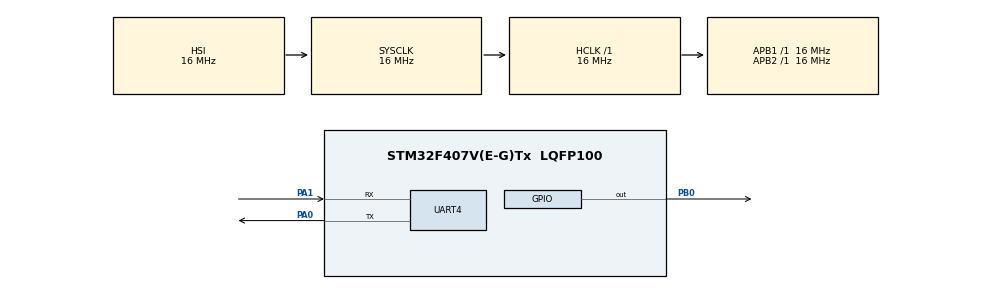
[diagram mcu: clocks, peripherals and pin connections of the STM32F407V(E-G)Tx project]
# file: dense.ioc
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Mcu.Family=STM32F4
Mcu.Name=STM32F407V(E-G)Tx
Mcu.Package=LQFP100
NVIC.PriorityGroup=NVIC_PRIORITYGROUP_4
PA0-WKUP.Mode=Asynchronous
PA0-WKUP.Signal=UART4_TX
PA1.Mode=Asynchronous
PA1.Signal=UART4_RX
PB0.Signal=GPIO_Output
ProjectManager.HeapSize=0x800
ProjectManager.StackSize=0x800
ProjectManager.TargetToolchain=Makefile
RCC.AHBFreq_Value=16000000
RCC.APB1Freq_Value=16000000
RCC.APB2Freq_Value=16000000
RCC.CortexFreq_Value=16000000
RCC.HSE_VALUE=25000000
RCC.HSI_VALUE=16000000
RCC.LSE_VALUE=32768
RCC.SYSCLKFreq_VALUE=16000000
RCC.VCOOutputFreq_Value=192000000
STMicroelectronics.X-CUBE-AI.4.1.0.ActivationBufferSizeList=40
STMicroelectronics.X-CUBE-AI.4.1.0.ApplicationCcArtificialOoIntelligenceJjApplication=Validation
STMicroelectronics.X-CUBE-AI.4.1.0.ArtificialOoIntelligenceJjApplication.cmp_version0=4.1.0
STMicroelectronics.X-CUBE-AI.4.1.0.ArtificialOoIntelligenceJjApplication.component0=Artificial Intelligence
STMicroelectronics.X-CUBE-AI.4.1.0.ArtificialOoIntelligenceJjApplication.description0=AI Application,Validation on Target
STMicroelectronics.X-CUBE-AI.4.1.0.ArtificialOoIntelligenceJjApplication.diagnostic0=This component should operate correctly.
STMicroelectronics.X-CUBE-AI.4.1.0.ArtificialOoIntelligenceJjApplication.documentation0=Documentation/index.html
STMicroelectronics.X-CUBE-AI.4.1.0.ArtificialOoIntelligenceJjApplication.group0=Application
STMicroelectronics.X-CUBE-AI.4.1.0.ArtificialOoIntelligenceJjApplication.paramName0=ApplicationCcArtificialOoIntelligenceJjApplication
STMicroelectronics.X-CUBE-AI.4.1.0.ArtificialOoIntelligenceJjApplication.sevirity0=none
STMicroelectronics.X-CUBE-AI.4.1.0.ArtificialOoIntelligenceJjApplication.variant0=Validation
STMicroelectronics.X-CUBE-AI.4.1.0.ArtificialOoIntelligenceJjApplication_bundle=Application
STMicroelectronics.X-CUBE-AI.4.1.0.ArtificialOoIntelligenceJjApplication_class=ArtificialOoIntelligence
STMicroelectronics.X-CUBE-AI.4.1.0.ArtificialOoIntelligenceJjApplication_name=X-CUBE-AI
STMicroelectronics.X-CUBE-AI.4.1.0.ArtificialOoIntelligenceJjApplication_size=1
STMicroelectronics.X-CUBE-AI.4.1.0.ArtificialOoIntelligenceJjApplication_vendor=STMicroelectronics
STMicroelectronics.X-CUBE-AI.4.1.0.ArtificialOoIntelligenceJjApplication_version=4.1.0
STMicroelectronics.X-CUBE-AI.4.1.0.ArtificialOoIntelligenceJjXAaCUBEAaAI.cmp_version0=4.1.0
STMicroelectronics.X-CUBE-AI.4.1.0.ArtificialOoIntelligenceJjXAaCUBEAaAI.component0=Artificial Intelligence
STMicroelectronics.X-CUBE-AI.4.1.0.ArtificialOoIntelligenceJjXAaCUBEAaAI.componentDoc0=nofile
STMicroelectronics.X-CUBE-AI.4.1.0.ArtificialOoIntelligenceJjXAaCUBEAaAI.description0=AI Core,Artificial Intelligence for STM32
STMicroelectronics.X-CUBE-AI.4.1.0.ArtificialOoIntelligenceJjXAaCUBEAaAI.diagnostic0=This component should operate correctly.
STMicroelectronics.X-CUBE-AI.4.1.0.ArtificialOoIntelligenceJjXAaCUBEAaAI.documentation0=Documentation/index.html
STMicroelectronics.X-CUBE-AI.4.1.0.ArtificialOoIntelligenceJjXAaCUBEAaAI.group0=Core
STMicroelectronics.X-CUBE-AI.4.1.0.ArtificialOoIntelligenceJjXAaCUBEAaAI.paramName0=XAaCUBEAaAICcArtificialOoIntelligenceJjCore
STMicroelectronics.X-CUBE-AI.4.1.0.ArtificialOoIntelligenceJjXAaCUBEAaAI.sevirity0=none
STMicroelectronics.X-CUBE-AI.4.1.0.ArtificialOoIntelligenceJjXAaCUBEAaAI_bundle=X-CUBE-AI
STMicroelectronics.X-CUBE-AI.4.1.0.ArtificialOoIntelligenceJjXAaCUBEAaAI_class=ArtificialOoIntelligence
STMicroelectronics.X-CUBE-AI.4.1.0.ArtificialOoIntelligenceJjXAaCUBEAaAI_name=X-CUBE-AI
STMicroelectronics.X-CUBE-AI.4.1.0.ArtificialOoIntelligenceJjXAaCUBEAaAI_size=1
STMicroelectronics.X-CUBE-AI.4.1.0.ArtificialOoIntelligenceJjXAaCUBEAaAI_vendor=STMicroelectronics
STMicroelectronics.X-CUBE-AI.4.1.0.ArtificialOoIntelligenceJjXAaCUBEAaAI_version=4.1.0
STMicroelectronics.X-CUBE-AI.4.1.0.HeapSize=0x800
STMicroelectronics.X-CUBE-AI.4.1.0.InternalRamActivationBufferMaxSize=AI_NETWORK_DATA_ACTIVATIONS_SIZE
STMicroelectronics.X-CUBE-AI.4.1.0.LatestDirectoryUsed-478d0beb4ce12c76428d81ba17a9bec7de5affbbac7ac4d617456a0664080c5e=/home/zingg/AIOnMCU/implementation/models
STMicroelectronics.X-CUBE-AI.4.1.0.ModelActualCompression-478d0beb4ce12c76428d81ba17a9bec7de5affbbac7ac4d617456a0664080c5e=0.0
STMicroelectronics.X-CUBE-AI.4.1.0.ModelCompression-478d0beb4ce12c76428d81ba17a9bec7de5affbbac7ac4d617456a0664080c5e=8
STMicroelectronics.X-CUBE-AI.4.1.0.ModelFlashOccupation-478d0beb4ce12c76428d81ba17a9bec7de5affbbac7ac4d617456a0664080c5e=4024
STMicroelectronics.X-CUBE-AI.4.1.0.ModelHashList=478d0beb4ce12c76428d81ba17a9bec7de5affbbac7ac4d617456a0664080c5e
STMicroelectronics.X-CUBE-AI.4.1.0.ModelKind-478d0beb4ce12c76428d81ba17a9bec7de5affbbac7ac4d617456a0664080c5e=KERAS
STMicroelectronics.X-CUBE-AI.4.1.0.ModelMacc-478d0beb4ce12c76428d81ba17a9bec7de5affbbac7ac4d617456a0664080c5e=7990
STMicroelectronics.X-CUBE-AI.4.1.0.ModelName-478d0beb4ce12c76428d81ba17a9bec7de5affbbac7ac4d617456a0664080c5e=network
STMicroelectronics.X-CUBE-AI.4.1.0.ModelNameList=network
STMicroelectronics.X-CUBE-AI.4.1.0.ModelRamOccupation-478d0beb4ce12c76428d81ba17a9bec7de5affbbac7ac4d617456a0664080c5e=40
STMicroelectronics.X-CUBE-AI.4.1.0.ModelStructureFile-478d0beb4ce12c76428d81ba17a9bec7de5affbbac7ac4d617456a0664080c5e=/home/zingg/AIOnMCU/implementation/models/mnist_min.h5
STMicroelectronics.X-CUBE-AI.4.1.0.ModelType-478d0beb4ce12c76428d81ba17a9bec7de5affbbac7ac4d617456a0664080c5e=Saved model
STMicroelectronics.X-CUBE-AI.4.1.0.StackSize=0x800
STMicroelectronics.X-CUBE-AI.4.1.0.WorkingBufferStartAddrList=0xFFFFFFFF
STMicroelectronics.X-CUBE-AI.4.1.0.XAaCUBEAaAICcArtificialOoIntelligenceJjCore=true
STMicroelectronics.X-CUBE-AI.4.1.0_ArtificialOoIntelligenceJjApplication_RteComponent0=\#define AI_VALIDATION
STMicroelectronics.X-CUBE-AI.4.1.0_ArtificialOoIntelligenceJjApplication_RteComponentsize=1
STMicroelectronics.X-CUBE-AI.4.1.0_ArtificialOoIntelligenceJjXAaCUBEAaAI_RteComponentsize=0
STMicroelectronics.X-CUBE-AI.4.1.0_MwName0=X-CUBE-AI
STMicroelectronics.X-CUBE-AI.4.1.0_MwName1=Application
STMicroelectronics.X-CUBE-AI.4.1.0_NumberOfMw=2
STMicroelectronics.X-CUBE-AI.4.1.0_description=Artificial Intelligence
STMicroelectronics.X-CUBE-AI.4.1.0_license=SLA0048.txt
UART4.VirtualMode=Asynchronous
VP_CRC_VS_CRC.Mode=CRC_Activate
VP_STMicroelectronics.X-CUBE-AI_VS_ArtificialOoIntelligenceJjXAaCUBEAaAI_4.1.0.Mode=ArtificialOoIntelligenceJjXAaCUBEAaAI
board=custom

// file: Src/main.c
/* USER CODE BEGIN Header */
/**
  ******************************************************************************
  * @file           : main.c
  * @brief          : Main program body
  ******************************************************************************
  * This notice applies to any and all portions of this file
  * that are not between comment pairs USER CODE BEGIN and
  * USER CODE END. Other portions of this file, whether
  * inserted by the user or by software development tools
  * are owned by their respective copyright owners.
  *
  * Copyright (c) 2019 STMicroelectronics International N.V.
  * All rights reserved.
  *
  * Redistribution and use in source and binary forms, with or without
  * modification, are permitted, provided that the following conditions are met:
  *
  * 1. Redistribution of source code must retain the above copyright notice,
  *    this list of conditions and the following disclaimer.
  * 2. Redistributions in binary form must reproduce the above copyright notice,
  *    this list of conditions and the following disclaimer in the documentation
  *    and/or other materials provided with the distribution.
  * 3. Neither the name of STMicroelectronics nor the names of other
  *    contributors to this software may be used to endorse or promote products
  *    derived from this software without specific written permission.
  * 4. This software, including modifications and/or derivative works of this
  *    software, must execute solely and exclusively on microcontroller or
  *    microprocessor devices manufactured by or for STMicroelectronics.
  * 5. Redistribution and use of this software other than as permitted under
  *    this license is void and will automatically terminate your rights under
  *    this license.
  *
  * THIS SOFTWARE IS PROVIDED BY STMICROELECTRONICS AND CONTRIBUTORS "AS IS"
  * AND ANY EXPRESS, IMPLIED OR STATUTORY WARRANTIES, INCLUDING, BUT NOT
  * LIMITED TO, THE IMPLIED WARRANTIES OF MERCHANTABILITY, FITNESS FOR A
  * PARTICULAR PURPOSE AND NON-INFRINGEMENT OF THIRD PARTY INTELLECTUAL PROPERTY
  * RIGHTS ARE DISCLAIMED TO THE FULLEST EXTENT PERMITTED BY LAW. IN NO EVENT
  * SHALL STMICROELECTRONICS OR CONTRIBUTORS BE LIABLE FOR ANY DIRECT, INDIRECT,
  * INCIDENTAL, SPECIAL, EXEMPLARY, OR CONSEQUENTIAL DAMAGES (INCLUDING, BUT NOT
  * LIMITED TO, PROCUREMENT OF SUBSTITUTE GOODS OR SERVICES; LOSS OF USE, DATA,
  * OR PROFITS; OR BUSINESS INTERRUPTION) HOWEVER CAUSED AND ON ANY THEORY OF
  * LIABILITY, WHETHER IN CONTRACT, STRICT LIABILITY, OR TORT (INCLUDING
  * NEGLIGENCE OR OTHERWISE) ARISING IN ANY WAY OUT OF THE USE OF THIS SOFTWARE,
  * EVEN IF ADVISED OF THE POSSIBILITY OF SUCH DAMAGE.
  *
  ******************************************************************************
  */
/* USER CODE END Header */

#include "main.h"
#include "app_x-cube-ai.h"

/* USER CODE BEGIN PD */
#define IMAGE_SIZE 784 /* MMNIST images have 28*28 pixels */

/* USER CODE END PD */

CRC_HandleTypeDef hcrc;

UART_HandleTypeDef huart4;

void SystemClock_Config(void);
static void MX_GPIO_Init(void);
static void MX_CRC_Init(void);
void MX_UART4_Init(void);

int main(void)
{
  /* USER CODE BEGIN 1 */
  uint8_t pred;
  uint16_t i;
  float mnist[IMAGE_SIZE * 2];
  uint8_t inputPicture[IMAGE_SIZE * 2];
  /* USER CODE END 1 */

  /* MCU Configuration--------------------------------------------------------*/

  /* Reset of all peripherals, Initializes the Flash interface and the Systick. */
  HAL_Init();

  /* Configure the system clock */
  SystemClock_Config();

  /* USER CODE BEGIN SysInit */
  MX_UART4_Init();

  /* USER CODE END SysInit */

  /* Initialize all configured peripherals */
  MX_GPIO_Init();
  MX_CRC_Init();
  MX_X_CUBE_AI_Init();

  /* Infinite loop */
  /* USER CODE BEGIN WHILE */
  while (1)
  {
    /* receive command */
    if (HAL_UART_Receive(&huart4, &pred, 1, 200) != HAL_OK)
      continue;

    switch (pred - 0)
    {
    case 's':
      /* handshake: receive 's' return 'X' */
      pred = 'X' + 0;
      HAL_UART_Transmit(&huart4, &pred, 1, 1000);
      pred = 2;
      HAL_UART_Transmit(&huart4, &pred, 1, 1000);
      break;

    case 'c':
      /* receive a picture from host */
      if (HAL_UART_Receive(&huart4, inputPicture, IMAGE_SIZE, 200) == HAL_OK)
      {

        /* scale into float range [0, 1] */
        for (i = 0; i < IMAGE_SIZE; i++)
          mnist[i] = ((float)inputPicture[i]) / 255.0;

        /* start time measurement */
        HAL_GPIO_WritePin(GPIOB, GPIO_PIN_0, GPIO_PIN_SET);

        /* run neural network to get a prediction of inputPicture */
        pred = MX_X_CUBE_AI_Process(mnist);

        /* stop time measurement */
        HAL_GPIO_WritePin(GPIOB, GPIO_PIN_0, GPIO_PIN_RESET);

        /* return the prediction */
        HAL_UART_Transmit(&huart4, &pred, 1U, 1000);
      }
      break;
    }
  }
  /* USER CODE END WHILE */
}

void SystemClock_Config(void)
{
  RCC_OscInitTypeDef RCC_OscInitStruct = {0};
  RCC_ClkInitTypeDef RCC_ClkInitStruct = {0};

  /** Configure the main internal regulator output voltage
  */
  __HAL_RCC_PWR_CLK_ENABLE();
  __HAL_PWR_VOLTAGESCALING_CONFIG(PWR_REGULATOR_VOLTAGE_SCALE1);
  /** Initializes the CPU, AHB and APB busses clocks
  */
  RCC_OscInitStruct.OscillatorType = RCC_OSCILLATORTYPE_HSI;
  RCC_OscInitStruct.HSIState = RCC_HSI_ON;
  RCC_OscInitStruct.HSICalibrationValue = RCC_HSICALIBRATION_DEFAULT;
  RCC_OscInitStruct.PLL.PLLState = RCC_PLL_NONE;
  if (HAL_RCC_OscConfig(&RCC_OscInitStruct) != HAL_OK)
  {
    Error_Handler();
  }
  /** Initializes the CPU, AHB and APB busses clocks
  */
  RCC_ClkInitStruct.ClockType = RCC_CLOCKTYPE_HCLK | RCC_CLOCKTYPE_SYSCLK | RCC_CLOCKTYPE_PCLK1 | RCC_CLOCKTYPE_PCLK2;
  RCC_ClkInitStruct.SYSCLKSource = RCC_SYSCLKSOURCE_HSI;
  RCC_ClkInitStruct.AHBCLKDivider = RCC_SYSCLK_DIV1;
  RCC_ClkInitStruct.APB1CLKDivider = RCC_HCLK_DIV1;
  RCC_ClkInitStruct.APB2CLKDivider = RCC_HCLK_DIV1;

  if (HAL_RCC_ClockConfig(&RCC_ClkInitStruct, FLASH_LATENCY_0) != HAL_OK)
  {
    Error_Handler();
  }
}

static void MX_CRC_Init(void)
{

  hcrc.Instance = CRC;
  if (HAL_CRC_Init(&hcrc) != HAL_OK)
  {
    Error_Handler();
  }
}

void MX_UART4_Init(void)
{

  huart4.Instance = UART4;
  huart4.Init.BaudRate = 256000;
  huart4.Init.WordLength = UART_WORDLENGTH_8B;
  huart4.Init.StopBits = UART_STOPBITS_1;
  huart4.Init.Parity = UART_PARITY_NONE;
  huart4.Init.Mode = UART_MODE_TX_RX;
  huart4.Init.HwFlowCtl = UART_HWCONTROL_NONE;
  huart4.Init.OverSampling = UART_OVERSAMPLING_16;
  if (HAL_UART_Init(&huart4) != HAL_OK)
  {
    Error_Handler();
  }
}

static void MX_GPIO_Init(void)
{
  GPIO_InitTypeDef GPIO_InitStruct = {0};

  /* GPIO Ports Clock Enable */
  __HAL_RCC_GPIOA_CLK_ENABLE();
  __HAL_RCC_GPIOB_CLK_ENABLE();

  /*Configure GPIO pin Output Level */
  HAL_GPIO_WritePin(GPIOB, GPIO_PIN_0, GPIO_PIN_RESET);

  /*Configure GPIO pin : PB0 */
  GPIO_InitStruct.Pin = GPIO_PIN_0;
  GPIO_InitStruct.Mode = GPIO_MODE_OUTPUT_PP;
  GPIO_InitStruct.Pull = GPIO_NOPULL;
  GPIO_InitStruct.Speed = GPIO_SPEED_FREQ_LOW;
  HAL_GPIO_Init(GPIOB, &GPIO_InitStruct);
}

void Error_Handler(void)
{
}

/************************ (C) COPYRIGHT STMicroelectronics *****END OF FILE****/
